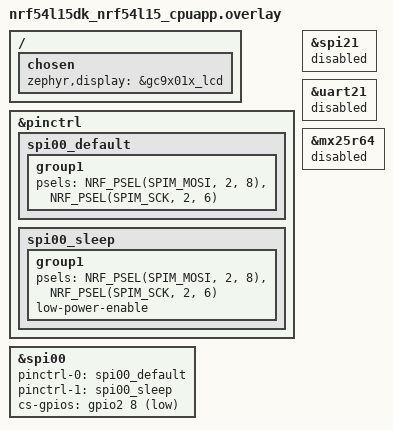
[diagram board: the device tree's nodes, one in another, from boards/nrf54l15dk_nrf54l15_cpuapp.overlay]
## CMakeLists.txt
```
cmake_minimum_required(VERSION 3.20.0)

find_package(Zephyr)
project(watch_prototype)

target_sources(app PRIVATE src/main.c)
```

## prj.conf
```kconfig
CONFIG_I2C=y
CONFIG_SENSOR=y
CONFIG_BMI270=y

# Diagnostics
CONFIG_SHELL=y
CONFIG_I2C_SHELL=y
#CONFIG_GPIO_SHELL=y
CONFIG_LOG=y
CONFIG_SENSOR_LOG_LEVEL_INF=y
CONFIG_DISPLAY_LOG_LEVEL_INF=y
CONFIG_MIPI_DBI_LOG_LEVEL_INF=y
CONFIG_SPI_LOG_LEVEL_WRN=y
CONFIG_I2C_LOG_LEVEL_INF=y


# Display
CONFIG_DISPLAY=y
CONFIG_MIPI_DBI=y
CONFIG_MIPI_DBI_SPI=y
CONFIG_GC9X01X=y
```

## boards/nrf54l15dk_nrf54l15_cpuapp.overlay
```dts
#include <zephyr/dt-bindings/display/panel.h>

/ {
	chosen {
		/delete-property/ nordic,pm-ext-flash;
		zephyr,display = &gc9x01x_lcd;
	};

	/* mipi_dbi { */
	/* 	compatible = "zephyr,mipi-dbi-spi"; */
	/* 	status = "okay"; */
	/* 	#address-cells = <1>; */
	/* 	#size-cells = <0>; */
	/* 	spi-dev = <&spi00>; */
	/* 	dc-gpios = <&gpio2 10 GPIO_ACTIVE_HIGH>; */
	/* 	reset-gpios = <&gpio2 6 GPIO_ACTIVE_LOW>; */
	/**/
	/* 	gc9x01x_lcd: gc9x01x_lcd@0 { */
	/* 		compatible = "galaxycore,gc9x01x"; */
	/* 		reg = <0>; */
	/* 		mipi-max-frequency = <DT_FREQ_M(100)>; */
	/* 		pixel-format = <PANEL_PIXEL_FORMAT_RGB_565>; */
	/* 		width = <240>; */
	/* 		height = <240>; */
	/* 		display-inversion; */
	/* 	}; */
	/* }; */
};

&pinctrl {
	spi00_default: spi00_default {
		group1 {
			psels = <NRF_PSEL(SPIM_MOSI, 2, 8)>,
					<NRF_PSEL(SPIM_SCK, 2, 6)>;
		};
	};

	spi00_sleep: spi00_sleep {
		group1 {
			psels = <NRF_PSEL(SPIM_MOSI, 2, 8)>,
					<NRF_PSEL(SPIM_SCK, 2, 6)>;
			low-power-enable;
		};
	};

	/* i2c21_default: i2c21_default { */
	/* 	group1 { */
	/* 		psels = <NRF_PSEL(TWIM_SDA, 1, 11)>, */
	/* 				<NRF_PSEL(TWIM_SCL, 1, 12)>; */
	/* 		bias-pull-up; */
	/* 	}; */
	/* }; */
	/**/
	/* i2c21_sleep: i2c21_sleep { */
	/* 	group1 { */
	/* 		psels = <NRF_PSEL(TWIM_SDA, 1, 11)>, */
	/* 				<NRF_PSEL(TWIM_SCL, 1, 12)>; */
	/* 		low-power-enable; */
	/* 	}; */
	/* }; */
};

&spi00 {
	status = "okay";
	pinctrl-0 = <&spi00_default>;
	pinctrl-1 = <&spi00_sleep>;
	pinctrl-names = "default", "sleep";
	cs-gpios = <&gpio2 8 GPIO_ACTIVE_LOW>;
};

/* &i2c21 { */
/* 	status = "okay"; */
/* 	pinctrl-0 = <&i2c21_default>; */
/* 	pinctrl-1 = <&i2c21_sleep>; */
/* 	pinctrl-names = "default", "sleep"; */
/* 	clock-frequency = <I2C_BITRATE_FAST>; */
/* 	zephyr,concat-buf-size = <257>; */
/**/
/* 	bosch_bmi270: bmi270@69 { */
/* 		compatible = "bosch,bmi270"; */
/* 		reg = <0x69>; */
/* 	}; */
/**/
/* 	cst816s: cst816s@15 { */
/* 		compatible = "hynitron,cst816s"; */
/* 		reg = <0x15>; */
/* 		irq-gpios = <&gpio1 5 GPIO_ACTIVE_LOW>; */
/* 		rst-gpios = <&gpio1 6 GPIO_ACTIVE_LOW>; */
/* 	}; */
/* }; */

&spi21 {
	status = "disabled";
};

&uart21 {
	status = "disabled";
};

&mx25r64 {
	status = "disabled";
};
```

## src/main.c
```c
/*
 * Copyright (c) 2012-2014 Wind River Systems, Inc.
 *
 * SPDX-License-Identifier: Apache-2.0
 */

#include <stdio.h>
#include <zephyr/kernel.h>
#include <zephyr/device.h>
#include <zephyr/drivers/sensor.h>
#include <zephyr/drivers/display.h>
#include <zephyr/sys/byteorder.h>
#include <zephyr/logging/log.h>

LOG_MODULE_REGISTER(main, LOG_LEVEL_INF);

#define COLOR_RED   0xF800
#define COLOR_GREEN 0x07E0
#define COLOR_BLUE  0x001F
#define COLOR_WHITE 0xFFFF

// /* --- BMI270 --- */
//
// int configure_bmi270(const struct device *const dev)
// {
// 	struct sensor_value full_scale, sampling_freq, oversampling;
//
// 	if (!device_is_ready(dev)) {
// 		LOG_ERR("BMI270 not ready");
// 		return -ENODEV;
// 	}
//
// 	LOG_INF("BMI270 found: %s", dev->name);
//
// 	full_scale.val1 = 2;
// 	full_scale.val2 = 0;
// 	sampling_freq.val1 = 100;
// 	sampling_freq.val2 = 0;
// 	oversampling.val1 = 1;
// 	oversampling.val2 = 0;
//
// 	sensor_attr_set(dev, SENSOR_CHAN_ACCEL_XYZ, SENSOR_ATTR_FULL_SCALE, &full_scale);
// 	sensor_attr_set(dev, SENSOR_CHAN_ACCEL_XYZ, SENSOR_ATTR_OVERSAMPLING, &oversampling);
// 	sensor_attr_set(dev, SENSOR_CHAN_ACCEL_XYZ, SENSOR_ATTR_SAMPLING_FREQUENCY, &sampling_freq);
//
// 	full_scale.val1 = 500;
// 	full_scale.val2 = 0;
// 	sampling_freq.val1 = 100;
// 	sampling_freq.val2 = 0;
// 	oversampling.val1 = 1;
// 	oversampling.val2 = 0;
//
// 	sensor_attr_set(dev, SENSOR_CHAN_GYRO_XYZ, SENSOR_ATTR_FULL_SCALE, &full_scale);
// 	sensor_attr_set(dev, SENSOR_CHAN_GYRO_XYZ, SENSOR_ATTR_OVERSAMPLING, &oversampling);
// 	sensor_attr_set(dev, SENSOR_CHAN_GYRO_XYZ, SENSOR_ATTR_SAMPLING_FREQUENCY, &sampling_freq);
//
// 	return 0;
// }
//
// void sample_bmi270(const struct device *const dev, struct sensor_value acc[3],
// 		   struct sensor_value gyr[3])
// {
// 	sensor_sample_fetch(dev);
// 	sensor_channel_get(dev, SENSOR_CHAN_ACCEL_XYZ, acc);
// 	sensor_channel_get(dev, SENSOR_CHAN_GYRO_XYZ, gyr);
//
// 	LOG_INF("AX: %d.%06d AY: %d.%06d AZ: %d.%06d "
// 		"GX: %d.%06d GY: %d.%06d GZ: %d.%06d",
// 		acc[0].val1, acc[0].val2, acc[1].val1, acc[1].val2,
// 		acc[2].val1, acc[2].val2, gyr[0].val1, gyr[0].val2,
// 		gyr[1].val1, gyr[1].val2, gyr[2].val1, gyr[2].val2);
// }

/* --- Main --- */

int main(void)
{
	// const struct device *const bmi270_dev = DEVICE_DT_GET_ONE(bosch_bmi270);
	const struct device *const display_dev = DEVICE_DT_GET(DT_CHOSEN(zephyr_display));

	// configure_bmi270(bmi270_dev);
	display_test(display_dev);

	// struct sensor_value acc[3], gyr[3];

	while (1) {
		k_sleep(K_MSEC(10));
		// sample_bmi270(bmi270_dev, acc, gyr);
	}

	return 0;
}
```
